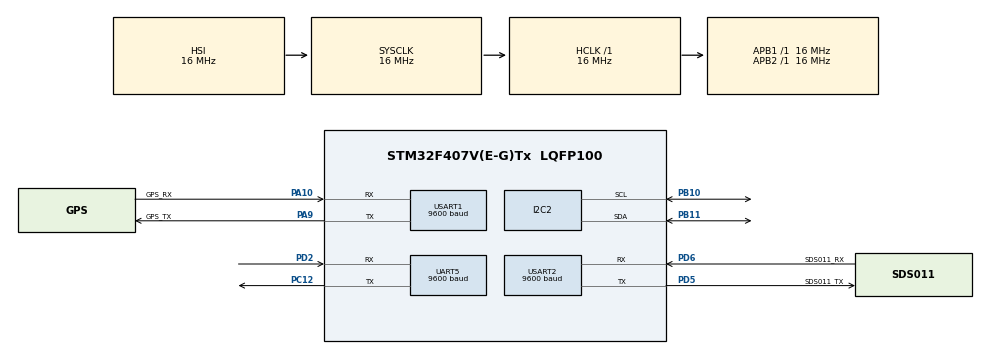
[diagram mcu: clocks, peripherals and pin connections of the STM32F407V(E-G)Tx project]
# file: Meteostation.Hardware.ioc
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Mcu.Family=STM32F4
Mcu.Name=STM32F407V(E-G)Tx
Mcu.Package=LQFP100
NVIC.PriorityGroup=NVIC_PRIORITYGROUP_4
NVIC.UART5_IRQn=true\:0\:0\:false\:false\:true\:true\:true
NVIC.USART1_IRQn=true\:0\:0\:false\:false\:true\:true\:true
NVIC.USART2_IRQn=true\:0\:0\:false\:false\:true\:true\:true
PA10.GPIO_Label=GPS_RX
PA10.Mode=Asynchronous
PA10.Signal=USART1_RX
PA9.GPIO_Label=GPS_TX
PA9.Mode=Asynchronous
PA9.Signal=USART1_TX
PB10.Mode=I2C
PB10.Signal=I2C2_SCL
PB11.Mode=I2C
PB11.Signal=I2C2_SDA
PC12.Mode=Asynchronous
PC12.Signal=UART5_TX
PD2.Mode=Asynchronous
PD2.Signal=UART5_RX
PD5.GPIO_Label=SDS011_TX
PD5.Mode=Asynchronous
PD5.Signal=USART2_TX
PD6.GPIO_Label=SDS011_RX
PD6.Mode=Asynchronous
PD6.Signal=USART2_RX
ProjectManager.HeapSize=0x200
ProjectManager.StackSize=0x400
ProjectManager.TargetToolchain=STM32CubeIDE
RCC.AHBFreq_Value=16000000
RCC.APB1Freq_Value=16000000
RCC.APB2Freq_Value=16000000
RCC.CortexFreq_Value=16000000
RCC.HSE_VALUE=25000000
RCC.HSI_VALUE=16000000
RCC.LSE_VALUE=32768
RCC.SYSCLKFreq_VALUE=16000000
RCC.VCOOutputFreq_Value=192000000
UART5.BaudRate=9600
UART5.VirtualMode=Asynchronous
USART1.BaudRate=9600
USART1.VirtualMode=VM_ASYNC
USART2.BaudRate=9600
USART2.VirtualMode=VM_ASYNC
board=custom

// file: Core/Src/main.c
/* USER CODE BEGIN Header */
/**
  ******************************************************************************
  * @file           : main.c
  * @brief          : Main program body
  ******************************************************************************
  * @attention
  *
  * <h2><center>&copy; Copyright (c) 2022 STMicroelectronics.
  * All rights reserved.</center></h2>
  *
  * This software component is licensed by ST under BSD 3-Clause license,
  * the "License"; You may not use this file except in compliance with the
  * License. You may obtain a copy of the License at:
  *                        opensource.org/licenses/BSD-3-Clause
  *
  ******************************************************************************
  */
/* USER CODE END Header */
#include "main.h"

/* USER CODE BEGIN Includes */
#include "sds011.h"
/* USER CODE END Includes */

I2C_HandleTypeDef hi2c2;

UART_HandleTypeDef huart5;
UART_HandleTypeDef huart1;
UART_HandleTypeDef huart2;

/* USER CODE BEGIN PV */

SDS sds;

uint8_t sdsResult[50];
uint16_t sdsResultSize = 0;

/* USER CODE END PV */

void SystemClock_Config(void);
static void MX_GPIO_Init(void);
static void MX_USART2_UART_Init(void);
static void MX_UART5_Init(void);
static void MX_USART1_UART_Init(void);
static void MX_I2C2_Init(void);

int main(void)
{

  /* MCU Configuration--------------------------------------------------------*/

  /* Reset of all peripherals, Initializes the Flash interface and the Systick. */
  HAL_Init();

  /* Configure the system clock */
  SystemClock_Config();

  /* Initialize all configured peripherals */
  MX_GPIO_Init();
  MX_USART2_UART_Init();
  MX_UART5_Init();
  MX_USART1_UART_Init();
  MX_I2C2_Init();
  /* USER CODE BEGIN 2 */
  sdsInit(&sds, &huart2);
  /* USER CODE END 2 */

  /* Infinite loop */
  while (1)
  {

    /* Work with SDS011 */

	  sdsResultSize = sprintf(sdsResult, "pm2.5: %f  pm10: %f \r\n", sds.pm_2_5, sds.pm_10);
	  HAL_UART_Transmit_IT(&huart5, sdsResult, sdsResultSize);
	  HAL_Delay(2000);

	  /*if (HAL_UART_Receive_IT(&huart1, testResult, 255) == HAL_OK)
	  {

	  }*/

  }
}

void SystemClock_Config(void)
{
  RCC_OscInitTypeDef RCC_OscInitStruct = {0};
  RCC_ClkInitTypeDef RCC_ClkInitStruct = {0};

  /** Configure the main internal regulator output voltage
  */
  __HAL_RCC_PWR_CLK_ENABLE();
  __HAL_PWR_VOLTAGESCALING_CONFIG(PWR_REGULATOR_VOLTAGE_SCALE1);
  /** Initializes the RCC Oscillators according to the specified parameters
  * in the RCC_OscInitTypeDef structure.
  */
  RCC_OscInitStruct.OscillatorType = RCC_OSCILLATORTYPE_HSI;
  RCC_OscInitStruct.HSIState = RCC_HSI_ON;
  RCC_OscInitStruct.HSICalibrationValue = RCC_HSICALIBRATION_DEFAULT;
  RCC_OscInitStruct.PLL.PLLState = RCC_PLL_NONE;
  if (HAL_RCC_OscConfig(&RCC_OscInitStruct) != HAL_OK)
  {
    Error_Handler();
  }
  /** Initializes the CPU, AHB and APB buses clocks
  */
  RCC_ClkInitStruct.ClockType = RCC_CLOCKTYPE_HCLK|RCC_CLOCKTYPE_SYSCLK
                              |RCC_CLOCKTYPE_PCLK1|RCC_CLOCKTYPE_PCLK2;
  RCC_ClkInitStruct.SYSCLKSource = RCC_SYSCLKSOURCE_HSI;
  RCC_ClkInitStruct.AHBCLKDivider = RCC_SYSCLK_DIV1;
  RCC_ClkInitStruct.APB1CLKDivider = RCC_HCLK_DIV1;
  RCC_ClkInitStruct.APB2CLKDivider = RCC_HCLK_DIV1;

  if (HAL_RCC_ClockConfig(&RCC_ClkInitStruct, FLASH_LATENCY_0) != HAL_OK)
  {
    Error_Handler();
  }
}

static void MX_I2C2_Init(void)
{

  hi2c2.Instance = I2C2;
  hi2c2.Init.ClockSpeed = 100000;
  hi2c2.Init.DutyCycle = I2C_DUTYCYCLE_2;
  hi2c2.Init.OwnAddress1 = 0;
  hi2c2.Init.AddressingMode = I2C_ADDRESSINGMODE_7BIT;
  hi2c2.Init.DualAddressMode = I2C_DUALADDRESS_DISABLE;
  hi2c2.Init.OwnAddress2 = 0;
  hi2c2.Init.GeneralCallMode = I2C_GENERALCALL_DISABLE;
  hi2c2.Init.NoStretchMode = I2C_NOSTRETCH_DISABLE;
  if (HAL_I2C_Init(&hi2c2) != HAL_OK)
  {
    Error_Handler();
  }

}

static void MX_UART5_Init(void)
{

  huart5.Instance = UART5;
  huart5.Init.BaudRate = 9600;
  huart5.Init.WordLength = UART_WORDLENGTH_8B;
  huart5.Init.StopBits = UART_STOPBITS_1;
  huart5.Init.Parity = UART_PARITY_NONE;
  huart5.Init.Mode = UART_MODE_TX_RX;
  huart5.Init.HwFlowCtl = UART_HWCONTROL_NONE;
  huart5.Init.OverSampling = UART_OVERSAMPLING_16;
  if (HAL_UART_Init(&huart5) != HAL_OK)
  {
    Error_Handler();
  }

}

static void MX_USART1_UART_Init(void)
{

  huart1.Instance = USART1;
  huart1.Init.BaudRate = 9600;
  huart1.Init.WordLength = UART_WORDLENGTH_8B;
  huart1.Init.StopBits = UART_STOPBITS_1;
  huart1.Init.Parity = UART_PARITY_NONE;
  huart1.Init.Mode = UART_MODE_TX_RX;
  huart1.Init.HwFlowCtl = UART_HWCONTROL_NONE;
  huart1.Init.OverSampling = UART_OVERSAMPLING_16;
  if (HAL_UART_Init(&huart1) != HAL_OK)
  {
    Error_Handler();
  }

}

static void MX_USART2_UART_Init(void)
{

  huart2.Instance = USART2;
  huart2.Init.BaudRate = 9600;
  huart2.Init.WordLength = UART_WORDLENGTH_8B;
  huart2.Init.StopBits = UART_STOPBITS_1;
  huart2.Init.Parity = UART_PARITY_NONE;
  huart2.Init.Mode = UART_MODE_TX_RX;
  huart2.Init.HwFlowCtl = UART_HWCONTROL_NONE;
  huart2.Init.OverSampling = UART_OVERSAMPLING_16;
  if (HAL_UART_Init(&huart2) != HAL_OK)
  {
    Error_Handler();
  }

}

static void MX_GPIO_Init(void)
{

  /* GPIO Ports Clock Enable */
  __HAL_RCC_GPIOB_CLK_ENABLE();
  __HAL_RCC_GPIOA_CLK_ENABLE();
  __HAL_RCC_GPIOC_CLK_ENABLE();
  __HAL_RCC_GPIOD_CLK_ENABLE();

}

/* USER CODE BEGIN 4 */
void HAL_UART_RxCpltCallback(UART_HandleTypeDef *huart)
{
	if (huart == &huart2)
	{
		sds_uart_RxCpltCallback(&sds, huart);
	}
}
/* USER CODE END 4 */

void Error_Handler(void)
{
  __disable_irq();
  while (1)
  {
  }
}

/************************ (C) COPYRIGHT STMicroelectronics *****END OF FILE****/
